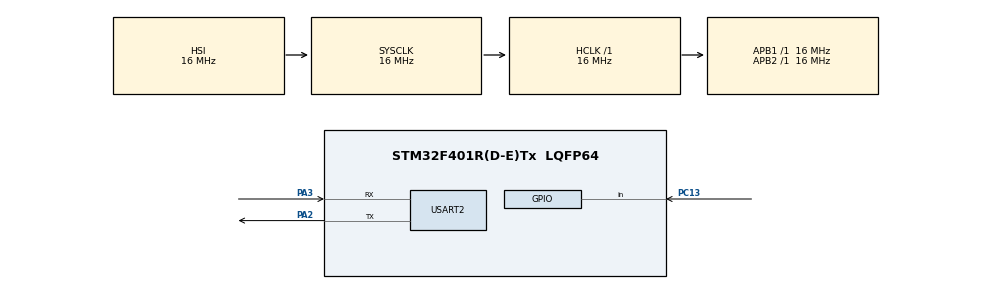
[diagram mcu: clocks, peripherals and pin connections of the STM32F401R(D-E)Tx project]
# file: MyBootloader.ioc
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Mcu.Family=STM32F4
Mcu.Name=STM32F401R(D-E)Tx
Mcu.Package=LQFP64
NVIC.PriorityGroup=NVIC_PRIORITYGROUP_4
NVIC.USART2_IRQn=true\:0\:0\:false\:false\:true\:true\:true
PA2.Mode=Asynchronous
PA2.Signal=USART2_TX
PA3.Mode=Asynchronous
PA3.Signal=USART2_RX
PC13-ANTI_TAMP.Signal=GPIO_Input
PH0\ -\ OSC_IN.Mode=HSE-External-Oscillator
PH0\ -\ OSC_IN.Signal=RCC_OSC_IN
PH1\ -\ OSC_OUT.Mode=HSE-External-Oscillator
PH1\ -\ OSC_OUT.Signal=RCC_OSC_OUT
ProjectManager.HeapSize=0x200
ProjectManager.StackSize=0x400
ProjectManager.TargetToolchain=STM32CubeIDE
RCC.AHBFreq_Value=16000000
RCC.APB1Freq_Value=16000000
RCC.APB1TimFreq_Value=16000000
RCC.APB2Freq_Value=16000000
RCC.APB2TimFreq_Value=16000000
RCC.CortexFreq_Value=16000000
RCC.HCLKFreq_Value=16000000
RCC.HSE_VALUE=25000000
RCC.HSI_VALUE=16000000
RCC.LSE_VALUE=32768
RCC.SYSCLKFreq_VALUE=16000000
RCC.VCOOutputFreq_Value=192000000
TIM2.Prescaler=15
USART2.VirtualMode=VM_ASYNC
VP_TIM2_VS_ClockSourceINT.Mode=Internal
board=custom

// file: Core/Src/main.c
/* USER CODE BEGIN Header */
/**
  ******************************************************************************
  * @file           : main.c
  * @brief          : Main program body
  ******************************************************************************
  * @attention
  *
  * Copyright (c) 2025 STMicroelectronics.
  * All rights reserved.
  *
  * This software is licensed under terms that can be found in the LICENSE file
  * in the root directory of this software component.
  * If no LICENSE file comes with this software, it is provided AS-IS.
  *
  ******************************************************************************
  */
/* USER CODE END Header */
#include "main.h"

/* USER CODE BEGIN Includes */

#include "SWUpdatePackageHandler.h"
/* USER CODE END Includes */

TIM_HandleTypeDef htim2;

UART_HandleTypeDef huart2;

/* USER CODE BEGIN PV */

// State Machine Variable

// Temporary fields for receiving data

/* USER CODE END PV */

void SystemClock_Config(void);
static void MX_GPIO_Init(void);
static void MX_TIM2_Init(void);
static void MX_USART2_UART_Init(void);

/* USER CODE BEGIN 0 */

int _write(int file, char *ptr, int len)
{
	int DataIdx;

	for (DataIdx = 0; DataIdx < len; DataIdx++)
	{
		ITM_SendChar(*ptr++);

	}
	return len;
}

/*int __io_putchar(int ch)
{
    HAL_UART_Transmit(&huart2, (uint8_t *)&ch, 1, HAL_MAX_DELAY);
    return ch;
}*/

void HAL_UART_RxCpltCallback(UART_HandleTypeDef *huart)
{

	if(huart->Instance == USART2)
	{
		SWUpdatePackageHandler_ReceiveFrame(huart);
	}
}

/* USER CODE END 0 */

int main(void)
{

  /* MCU Configuration--------------------------------------------------------*/

  /* Reset of all peripherals, Initializes the Flash interface and the Systick. */
  HAL_Init();

  /* Configure the system clock */
  SystemClock_Config();

  /* Initialize all configured peripherals */
  MX_GPIO_Init();
  MX_TIM2_Init();
  MX_USART2_UART_Init();
  /* USER CODE BEGIN 2 */

  printf("\r\n");
  printf("---------------------------------------------------------\r\n");
  printf("                 STM32 BOOTLOADER v1.0                   \r\n");
  printf("                 System Initializing...                  \r\n");
  printf("---------------------------------------------------------\r\n");

  printf("[BOOT] >>> Initializing system core...\r\n");

  SWUpdatePackageHandler_Init(&huart2);

  //printf("[BOOT] >>> Reading Configuration from FLASH...\r\n");
  //uint8_t FlashConfig = *(uint8_t*)CONFIG_ADDRESS;
  //printf("[BOOT] >>> Value Read From Flash: 0x%02X \r\n", FlashConfig);
  SWUpdateMode_Start();
  /* USER CODE END 2 */

  /* Infinite loop */
  while (1)
  {

  }
}

void SystemClock_Config(void)
{
  RCC_OscInitTypeDef RCC_OscInitStruct = {0};
  RCC_ClkInitTypeDef RCC_ClkInitStruct = {0};

  /** Configure the main internal regulator output voltage
  */
  __HAL_RCC_PWR_CLK_ENABLE();
  __HAL_PWR_VOLTAGESCALING_CONFIG(PWR_REGULATOR_VOLTAGE_SCALE2);
  /** Initializes the RCC Oscillators according to the specified parameters
  * in the RCC_OscInitTypeDef structure.
  */
  RCC_OscInitStruct.OscillatorType = RCC_OSCILLATORTYPE_HSI;
  RCC_OscInitStruct.HSIState = RCC_HSI_ON;
  RCC_OscInitStruct.HSICalibrationValue = RCC_HSICALIBRATION_DEFAULT;
  RCC_OscInitStruct.PLL.PLLState = RCC_PLL_NONE;
  if (HAL_RCC_OscConfig(&RCC_OscInitStruct) != HAL_OK)
  {
    Error_Handler();
  }
  /** Initializes the CPU, AHB and APB buses clocks
  */
  RCC_ClkInitStruct.ClockType = RCC_CLOCKTYPE_HCLK|RCC_CLOCKTYPE_SYSCLK
                              |RCC_CLOCKTYPE_PCLK1|RCC_CLOCKTYPE_PCLK2;
  RCC_ClkInitStruct.SYSCLKSource = RCC_SYSCLKSOURCE_HSI;
  RCC_ClkInitStruct.AHBCLKDivider = RCC_SYSCLK_DIV1;
  RCC_ClkInitStruct.APB1CLKDivider = RCC_HCLK_DIV1;
  RCC_ClkInitStruct.APB2CLKDivider = RCC_HCLK_DIV1;

  if (HAL_RCC_ClockConfig(&RCC_ClkInitStruct, FLASH_LATENCY_0) != HAL_OK)
  {
    Error_Handler();
  }
}

static void MX_TIM2_Init(void)
{

  TIM_ClockConfigTypeDef sClockSourceConfig = {0};
  TIM_MasterConfigTypeDef sMasterConfig = {0};

  htim2.Instance = TIM2;
  htim2.Init.Prescaler = 15;
  htim2.Init.CounterMode = TIM_COUNTERMODE_UP;
  htim2.Init.Period = 4294967295;
  htim2.Init.ClockDivision = TIM_CLOCKDIVISION_DIV1;
  htim2.Init.AutoReloadPreload = TIM_AUTORELOAD_PRELOAD_DISABLE;
  if (HAL_TIM_Base_Init(&htim2) != HAL_OK)
  {
    Error_Handler();
  }
  sClockSourceConfig.ClockSource = TIM_CLOCKSOURCE_INTERNAL;
  if (HAL_TIM_ConfigClockSource(&htim2, &sClockSourceConfig) != HAL_OK)
  {
    Error_Handler();
  }
  sMasterConfig.MasterOutputTrigger = TIM_TRGO_RESET;
  sMasterConfig.MasterSlaveMode = TIM_MASTERSLAVEMODE_DISABLE;
  if (HAL_TIMEx_MasterConfigSynchronization(&htim2, &sMasterConfig) != HAL_OK)
  {
    Error_Handler();
  }

}

static void MX_USART2_UART_Init(void)
{

  huart2.Instance = USART2;
  huart2.Init.BaudRate = 115200;
  huart2.Init.WordLength = UART_WORDLENGTH_8B;
  huart2.Init.StopBits = UART_STOPBITS_1;
  huart2.Init.Parity = UART_PARITY_NONE;
  huart2.Init.Mode = UART_MODE_TX_RX;
  huart2.Init.HwFlowCtl = UART_HWCONTROL_NONE;
  huart2.Init.OverSampling = UART_OVERSAMPLING_16;
  if (HAL_UART_Init(&huart2) != HAL_OK)
  {
    Error_Handler();
  }

}

static void MX_GPIO_Init(void)
{
  GPIO_InitTypeDef GPIO_InitStruct = {0};

  /* GPIO Ports Clock Enable */
  __HAL_RCC_GPIOC_CLK_ENABLE();
  __HAL_RCC_GPIOH_CLK_ENABLE();
  __HAL_RCC_GPIOA_CLK_ENABLE();

  /*Configure GPIO pin : PC13 */
  GPIO_InitStruct.Pin = GPIO_PIN_13;
  GPIO_InitStruct.Mode = GPIO_MODE_INPUT;
  GPIO_InitStruct.Pull = GPIO_NOPULL;
  HAL_GPIO_Init(GPIOC, &GPIO_InitStruct);

}

void Error_Handler(void)
{
  __disable_irq();
  while (1)
  {
  }
}
